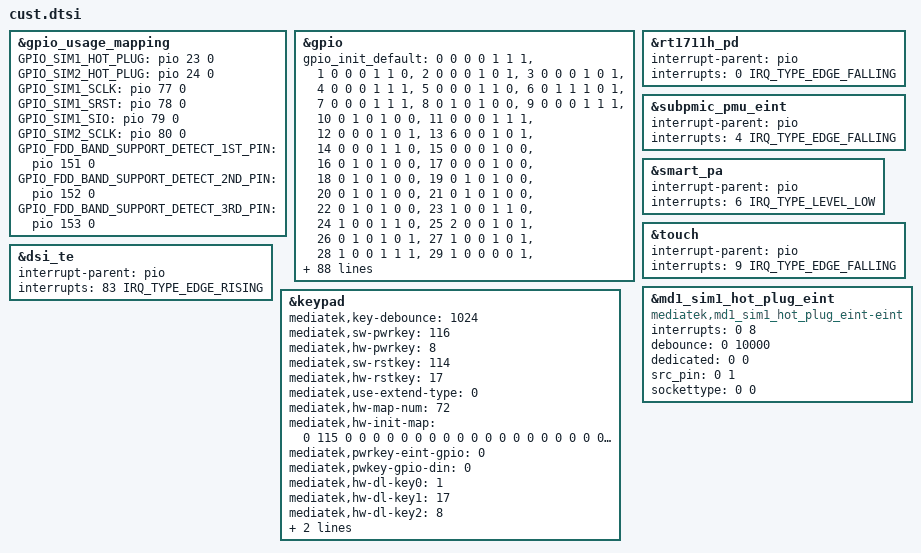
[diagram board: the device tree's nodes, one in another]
/*
 * Generated by MTK SP DrvGen Version: 3.5.160809 for MT6789.
 * 2023-05-25 10:21:08
 * Do Not Modify The File.
 * Copyright Mediatek Inc. (c) 2016.
*/

/*************************
 * ADC DTSI File
*************************/



/*************************
 * CLK_BUF DTSI File
*************************/



/*************************
 * I2C DTSI File
*************************/



/*************************
 * GPIO DTSI File
*************************/

&gpio_usage_mapping {
	GPIO_SIM1_HOT_PLUG = <&pio 23 0>;
	GPIO_SIM2_HOT_PLUG = <&pio 24 0>;
	GPIO_SIM1_SCLK = <&pio 77 0>;
	GPIO_SIM1_SRST = <&pio 78 0>;
	GPIO_SIM1_SIO = <&pio 79 0>;
	GPIO_SIM2_SCLK = <&pio 80 0>;
	GPIO_FDD_BAND_SUPPORT_DETECT_1ST_PIN = <&pio 151 0>;
	GPIO_FDD_BAND_SUPPORT_DETECT_2ND_PIN = <&pio 152 0>;
	GPIO_FDD_BAND_SUPPORT_DETECT_3RD_PIN = <&pio 153 0>;
};

&gpio{
	gpio_init_default = <0 0 0 0 1 1 1>,
		<1 0 0 0 1 1 0>,
		<2 0 0 0 1 0 1>,
		<3 0 0 0 1 0 1>,
		<4 0 0 0 1 1 1>,
		<5 0 0 0 1 1 0>,
		<6 0 1 1 1 0 1>,
		<7 0 0 0 1 1 1>,
		<8 0 1 0 1 0 0>,
		<9 0 0 0 1 1 1>,
		<10 0 1 0 1 0 0>,
		<11 0 0 0 1 1 1>,
		<12 0 0 0 1 0 1>,
		<13 6 0 0 1 0 1>,
		<14 0 0 0 1 1 0>,
		<15 0 0 0 1 0 0>,
		<16 0 1 0 1 0 0>,
		<17 0 0 0 1 0 0>,
		<18 0 1 0 1 0 0>,
		<19 0 1 0 1 0 0>,
		<20 0 1 0 1 0 0>,
		<21 0 1 0 1 0 0>,
		<22 0 1 0 1 0 0>,
		<23 1 0 0 1 1 0>,
		<24 1 0 0 1 1 0>,
		<25 2 0 0 1 0 1>,
		<26 0 1 0 1 0 1>,
		<27 1 0 0 1 0 1>,
		<28 1 0 0 1 1 1>,
		<29 1 0 0 0 0 1>,
		<30 1 0 0 0 0 1>,
		<31 1 0 0 0 0 1>,
		<32 1 0 0 0 0 1>,
		<33 1 0 0 1 0 1>,
		<34 6 0 0 1 0 0>,
		<35 6 0 0 1 0 0>,
		<36 0 1 0 1 0 0>,
		<37 0 1 0 1 0 0>,
		<38 2 0 0 0 0 1>,
		<39 2 0 0 0 0 1>,
		<40 2 0 0 0 0 1>,
		<41 2 0 0 1 0 1>,
		<42 1 1 0 0 0 0>,
		<43 1 1 0 0 0 0>,
		<44 1 1 0 0 0 0>,
		<45 1 0 0 0 0 0>,
		<46 6 0 0 1 0 0>,
		<47 6 0 0 1 0 0>,
		<48 6 0 0 0 0 0>,
		<49 6 0 0 1 0 0>,
		<50 2 0 0 0 0 1>,
		<51 2 0 0 0 0 1>,
		<52 2 0 0 0 0 1>,
		<53 2 0 0 1 0 1>,
		<54 0 0 0 0 0 1>,
		<64 0 0 0 1 0 0>,
		<66 1 0 0 1 1 0>,
		<67 1 0 0 1 1 0>,
		<68 0 1 0 1 0 1>,
		<69 0 0 0 1 1 1>,
		<77 1 0 0 0 0 1>,
		<78 1 0 0 0 0 1>,
		<79 1 0 0 1 1 1>,
		<80 1 0 0 0 0 1>,
		<81 0 1 0 1 0 1>,
		<82 0 1 0 1 0 1>,
		<83 1 0 0 1 0 1>,
		<84 1 0 0 0 0 1>,
		<85 0 1 0 1 0 1>,
		<86 1 0 0 1 0 0>,
		<87 1 0 0 1 0 0>,
		<88 1 0 0 1 0 0>,
		<89 1 0 0 1 0 0>,
		<90 1 0 0 1 0 0>,
		<91 1 0 0 1 0 0>,
		<92 1 0 0 1 0 0>,
		<93 1 0 0 1 0 0>,
		<94 1 0 0 1 0 0>,
		<95 1 0 0 1 0 0>,
		<96 1 0 0 1 0 0>,
		<97 1 0 0 1 0 0>,
		<98 1 0 0 1 0 0>,
		<99 1 0 0 1 0 0>,
		<100 1 0 0 1 0 0>,
		<101 1 0 0 1 0 0>,
		<102 1 0 0 1 0 0>,
		<103 0 0 0 1 1 0>,
		<104 2 0 0 0 0 0>,
		<105 1 0 0 1 0 0>,
		<106 1 0 0 1 0 0>,
		<107 1 0 0 1 0 0>,
		<108 1 0 0 1 0 0>,
		<109 1 0 0 1 0 0>,
		<110 1 0 0 1 0 0>,
		<111 1 0 0 1 0 0>,
		<112 1 0 0 0 0 0>,
		<113 1 0 0 1 0 0>,
		<114 1 0 0 0 0 0>,
		<115 1 0 0 1 0 0>,
		<116 1 0 0 0 0 0>,
		<117 1 0 0 1 0 0>,
		<118 1 0 0 0 0 0>,
		<119 1 0 0 1 0 0>,
		<120 1 0 0 0 0 0>,
		<121 1 0 0 1 0 0>,
		<122 1 0 0 0 0 0>,
		<123 1 0 0 0 0 0>,
		<124 1 0 0 1 0 0>,
		<125 1 0 0 1 0 0>,
		<126 1 0 0 1 0 0>,
		<127 1 0 0 1 0 0>,
		<128 1 0 0 1 0 0>,
		<129 1 0 0 1 0 0>,
		<130 1 0 0 1 1 1>,
		<131 1 0 0 1 1 1>,
		<132 2 0 0 1 1 0>,
		<133 2 0 0 1 1 0>,
		<134 0 1 0 1 0 0>,
		<135 0 1 0 1 0 0>,
		<136 0 1 0 1 0 1>,
		<137 0 0 0 1 0 1>,
		<138 1 0 0 1 1 1>,
		<139 1 0 0 1 1 1>,
		<140 1 0 0 1 1 1>,
		<141 1 0 0 1 1 1>,
		<142 1 0 0 1 1 1>,
		<143 1 0 0 1 1 1>,
		<144 1 0 0 1 1 1>,
		<145 1 0 0 1 1 1>,
		<146 1 0 0 1 1 1>,
		<147 1 0 0 1 1 1>,
		<148 2 0 0 1 1 1>,
		<149 2 0 0 1 1 1>,
		<150 0 0 0 1 0 0>,
		<151 0 0 0 1 0 0>,
		<152 0 0 0 1 0 0>,
		<153 0 0 0 1 0 0>,
		<154 0 1 0 1 0 1>,
		<155 0 1 0 1 0 1>,
		<156 0 1 0 1 0 1>,
		<157 0 1 0 1 0 1>,
		<158 0 1 0 1 0 0>,
		<159 0 1 0 1 0 0>,
		<160 1 0 0 0 0 1>,
		<161 1 0 0 0 0 1>,
		<162 1 0 0 0 0 1>,
		<163 1 0 0 1 0 1>,
		<164 1 0 0 0 0 1>,
		<165 1 0 0 0 0 1>,
		<166 1 0 0 0 0 1>,
		<167 1 0 0 1 0 1>,
		<168 1 0 0 0 0 0>,
		<169 1 0 0 0 0 1>,
		<170 1 0 0 0 0 1>,
		<171 1 0 0 0 0 1>,
		<172 1 0 0 0 0 1>,
		<173 1 0 0 1 0 1>,
		<174 1 0 0 1 0 1>,
		<175 1 0 0 1 0 1>,
		<176 1 0 0 1 0 1>,
		<177 0 0 0 1 0 0>,
		<178 0 0 0 1 0 0>,
		<179 0 0 0 1 0 0>,
		<180 0 0 0 1 0 0>,
		<181 0 0 0 1 0 0>,
		<182 0 0 0 1 0 0>,
		<183 0 0 0 1 0 0>,
		<184 0 0 0 1 0 0>,
		<185 0 0 0 1 0 0>,
		<186 1 0 0 1 1 1>,
		<187 1 0 0 1 1 1>,
		<188 0 0 0 1 0 0>,
		<189 0 0 0 1 0 0>,
		<190 0 0 0 1 0 0>,
		<191 0 0 0 1 0 0>,
		<192 0 0 0 1 0 0>,
		<193 0 0 0 1 0 0>,
		<194 0 0 0 1 0 0>,
		<195 0 0 0 1 0 0>,
		<196 0 0 0 1 0 0>,
		<197 0 0 0 1 0 0>,
		<198 0 0 0 1 0 0>,
		<199 0 0 0 1 0 0>,
		<200 0 0 0 1 0 0>,
		<201 0 0 0 1 0 0>,
		<202 0 0 0 1 0 0>,
		<203 0 0 0 1 0 0>,
		<204 0 0 0 1 0 0>,
		<205 0 0 0 1 0 0>,
		<206 0 0 0 1 0 0>,
		<207 0 0 0 1 0 0>,
		<208 0 0 0 1 0 0>,
		<209 0 0 0 1 0 0>,
		<210 0 0 0 1 0 0>,
		<211 0 0 0 1 0 0>,
		<212 0 0 0 1 0 0>,
		<213 0 0 0 1 0 0>,
		<214 0 0 0 1 0 0>,
		<215 0 0 0 1 0 0>,
		<216 0 0 0 1 0 0>,
		<217 0 0 0 1 0 0>,
		<218 0 0 0 1 0 0>,
		<219 0 0 0 1 0 0>,
		<220 0 0 0 1 0 0>,
		<221 0 0 0 1 0 0>;
};


/*************************
 * EINT DTSI File
*************************/

#include <dt-bindings/interrupt-controller/irq.h>
#include <dt-bindings/interrupt-controller/arm-gic.h>

&rt1711h_pd {
	interrupt-parent = <&pio>;
	interrupts = <0 IRQ_TYPE_EDGE_FALLING>;
	status = "okay";
};

&subpmic_pmu_eint {
	interrupt-parent = <&pio>;
	interrupts = <4 IRQ_TYPE_EDGE_FALLING>;
	status = "okay";
};

&smart_pa {
	interrupt-parent = <&pio>;
	interrupts = <6 IRQ_TYPE_LEVEL_LOW>;
	status = "okay";
};

&touch {
	interrupt-parent = <&pio>;
	interrupts = <9 IRQ_TYPE_EDGE_FALLING>;
	status = "okay";
};

&dsi_te {
	interrupt-parent = <&pio>;
	interrupts = <83 IRQ_TYPE_EDGE_RISING>;
	status = "okay";
};



/*************************
 * MD1_EINT DTSI File
*************************/

&md1_sim1_hot_plug_eint {
	compatible = "mediatek,md1_sim1_hot_plug_eint-eint";
	interrupts = <0 8>;
	debounce = <0 10000>;
	dedicated = <0 0>;
	src_pin = <0 1>;
	sockettype = <0 0>;
	status = "okay";
};



/*************************
 * PMIC DTSI File
*************************/



/*************************
 * POWER DTSI File
*************************/



/*************************
 * KPD DTSI File
*************************/

&keypad {
	mediatek,key-debounce = <1024>;
	mediatek,sw-pwrkey = <116>;
	mediatek,hw-pwrkey = <8>;
	mediatek,sw-rstkey  = <114>;
	mediatek,hw-rstkey = <17>;
	mediatek,use-extend-type = <0>;
	/*HW Keycode [0~71] -> Linux Keycode*/
	mediatek,hw-map-num = <72>;
	mediatek,hw-init-map = <0 115 0 0 0 0 0 0 0 0 0 0 0 0 0 0 0 0 0 0 0 0 0 0 0 0 0 0 0 0 0 0 0 0 0 0 0 0 0 0 0 0 0 0 0 0 0 0 0 0 0 0 0 0 0 0 0 0 0 0 0 0 0 0 0 0 0 0 0 0 0 0 >;
	mediatek,pwrkey-eint-gpio = <0>;
	mediatek,pwkey-gpio-din  = <0>;
	mediatek,hw-dl-key0 = <1>;
	mediatek,hw-dl-key1 = <17>;
	mediatek,hw-dl-key2 = <8>;
	mediatek,hw-recovery-key = <1>;
	mediatek,hw-factory-key = <17>;
	status = "okay";
};


